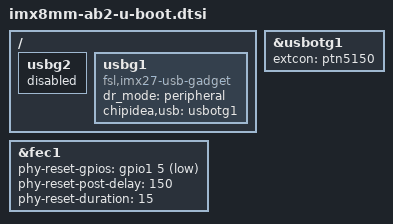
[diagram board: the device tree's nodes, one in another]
// SPDX-License-Identifier: GPL-2.0+
/*
 * Copyright 2020 NXP
 */

#include "imx8mm-evk-u-boot.dtsi"

/ {
	usbg2: usbg2 {
		status = "disabled";
	};

	usbg1: usbg1 {
		compatible = "fsl,imx27-usb-gadget";
		dr_mode = "peripheral";
		chipidea,usb = <&usbotg1>;
		status = "okay";
	};
};

&fec1 {
	phy-reset-gpios = <&gpio1 5 GPIO_ACTIVE_LOW>;
	phy-reset-post-delay = <150>;
	phy-reset-duration = <15>;
};

&usbotg1 {
	status = "okay";
	extcon = <&ptn5150>;
};
